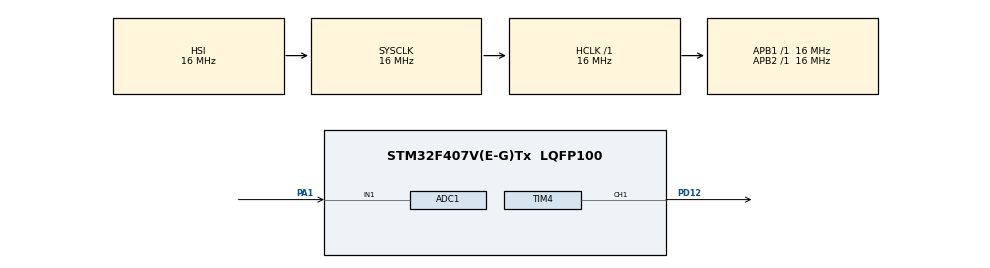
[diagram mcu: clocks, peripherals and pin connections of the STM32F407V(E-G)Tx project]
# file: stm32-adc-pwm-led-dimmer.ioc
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ADC1.Channel-0\#ChannelRegularConversion=ADC_CHANNEL_1
ADC1.NbrOfConversionFlag=1
ADC1.Rank-0\#ChannelRegularConversion=1
ADC1.SamplingTime-0\#ChannelRegularConversion=ADC_SAMPLETIME_3CYCLES
ADC1.master=1
Mcu.Family=STM32F4
Mcu.Name=STM32F407V(E-G)Tx
Mcu.Package=LQFP100
NVIC.PriorityGroup=NVIC_PRIORITYGROUP_4
PA1.Signal=ADCx_IN1
PD12.Signal=S_TIM4_CH1
ProjectManager.HeapSize=0x200
ProjectManager.StackSize=0x400
ProjectManager.TargetToolchain=STM32CubeIDE
RCC.AHBFreq_Value=16000000
RCC.APB1Freq_Value=16000000
RCC.APB2Freq_Value=16000000
RCC.CortexFreq_Value=16000000
RCC.HSE_VALUE=25000000
RCC.HSI_VALUE=16000000
RCC.LSE_VALUE=32768
RCC.SYSCLKFreq_VALUE=16000000
RCC.VCOOutputFreq_Value=192000000
SH.ADCx_IN1.0=ADC1_IN1,IN1
SH.S_TIM4_CH1.0=TIM4_CH1,PWM Generation1 CH1
TIM4.AutoReloadPreload=TIM_AUTORELOAD_PRELOAD_ENABLE
TIM4.Channel-PWM\ Generation1\ CH1=TIM_CHANNEL_1
TIM4.Period=4095
TIM4.Prescaler=15
board=custom

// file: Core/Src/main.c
/* USER CODE BEGIN Header */
/**
 ******************************************************************************
 * @file           : main.c
 * @brief          : Main program body
 ******************************************************************************
 * @attention
 *
 * Copyright (c) 2026 STMicroelectronics.
 * All rights reserved.
 *
 * This software is licensed under terms that can be found in the LICENSE file
 * in the root directory of this software component.
 * If no LICENSE file comes with this software, it is provided AS-IS.
 *
 ******************************************************************************
 */
/* USER CODE END Header */
#include "main.h"

/* USER CODE BEGIN PD */
/**
 * @brief  Sampling period between two ADC conversions (in milliseconds).
 */
#define ADC_SAMPLING_PERIOD_MS  (20U)
/* USER CODE END PD */

ADC_HandleTypeDef hadc1;
TIM_HandleTypeDef htim4;

void SystemClock_Config(void);
static void MX_GPIO_Init(void);
static void MX_ADC1_Init(void);
static void MX_TIM4_Init(void);
/* USER CODE BEGIN PFP */
static uint16_t ReadAdcValue(void);
/* USER CODE END PFP */

/* USER CODE BEGIN 0 */
/**
 * @brief  Read the potentiometer ADC value.
 * @retval 12-bit ADC conversion result (0-4095).
 */
static uint16_t ReadAdcValue(void)
{
	uint16_t adc_value = 0U;

	if (HAL_ADC_Start(&hadc1) != HAL_OK)
	{
		Error_Handler();
	}

	if (HAL_ADC_PollForConversion(&hadc1, 1U) != HAL_OK)
	{
		Error_Handler();
	}

	adc_value = (uint16_t) HAL_ADC_GetValue(&hadc1);

	if (HAL_ADC_Stop(&hadc1) != HAL_OK)
	{
		Error_Handler();
	}

	return adc_value;
}
/* USER CODE END 0 */

int main(void)
{
	/* USER CODE BEGIN 1 */
	uint16_t adc_value = 0U;
	/* USER CODE END 1 */

	/* MCU Configuration--------------------------------------------------------*/

	/* Reset of all peripherals, Initializes the Flash interface and the Systick. */
	HAL_Init();

	/* Configure the system clock */
	SystemClock_Config();

	/* Initialize all configured peripherals */
	MX_GPIO_Init();
	MX_ADC1_Init();
	MX_TIM4_Init();
	/* USER CODE BEGIN 2 */
	if (HAL_TIM_PWM_Start(&htim4, TIM_CHANNEL_1) != HAL_OK)
	{
		Error_Handler();
	}
	/* USER CODE END 2 */

	/* Infinite loop */
	/* USER CODE BEGIN WHILE */
	while (1)
	{
		adc_value = ReadAdcValue();
		__HAL_TIM_SET_COMPARE(&htim4, TIM_CHANNEL_1, adc_value);
		HAL_Delay(ADC_SAMPLING_PERIOD_MS);
		/* USER CODE END WHILE */

	}
}

void SystemClock_Config(void)
{
	RCC_OscInitTypeDef RCC_OscInitStruct = { 0 };
	RCC_ClkInitTypeDef RCC_ClkInitStruct = { 0 };

	/** Configure the main internal regulator output voltage
	 */
	__HAL_RCC_PWR_CLK_ENABLE();
	__HAL_PWR_VOLTAGESCALING_CONFIG(PWR_REGULATOR_VOLTAGE_SCALE1);

	/** Initializes the RCC Oscillators according to the specified parameters
	 * in the RCC_OscInitTypeDef structure.
	 */
	RCC_OscInitStruct.OscillatorType = RCC_OSCILLATORTYPE_HSI;
	RCC_OscInitStruct.HSIState = RCC_HSI_ON;
	RCC_OscInitStruct.HSICalibrationValue = RCC_HSICALIBRATION_DEFAULT;
	RCC_OscInitStruct.PLL.PLLState = RCC_PLL_NONE;
	if (HAL_RCC_OscConfig(&RCC_OscInitStruct) != HAL_OK) {
		Error_Handler();
	}

	/** Initializes the CPU, AHB and APB buses clocks
	 */
	RCC_ClkInitStruct.ClockType = RCC_CLOCKTYPE_HCLK | RCC_CLOCKTYPE_SYSCLK
			| RCC_CLOCKTYPE_PCLK1 | RCC_CLOCKTYPE_PCLK2;
	RCC_ClkInitStruct.SYSCLKSource = RCC_SYSCLKSOURCE_HSI;
	RCC_ClkInitStruct.AHBCLKDivider = RCC_SYSCLK_DIV1;
	RCC_ClkInitStruct.APB1CLKDivider = RCC_HCLK_DIV1;
	RCC_ClkInitStruct.APB2CLKDivider = RCC_HCLK_DIV1;

	if (HAL_RCC_ClockConfig(&RCC_ClkInitStruct, FLASH_LATENCY_0) != HAL_OK) {
		Error_Handler();
	}
}

static void MX_ADC1_Init(void)
{

	ADC_ChannelConfTypeDef sConfig = { 0 };

	/** Configure the global features of the ADC (Clock, Resolution, Data Alignment and number of conversion)
	 */
	hadc1.Instance = ADC1;
	hadc1.Init.ClockPrescaler = ADC_CLOCK_SYNC_PCLK_DIV2;
	hadc1.Init.Resolution = ADC_RESOLUTION_12B;
	hadc1.Init.ScanConvMode = DISABLE;
	hadc1.Init.ContinuousConvMode = DISABLE;
	hadc1.Init.DiscontinuousConvMode = DISABLE;
	hadc1.Init.ExternalTrigConvEdge = ADC_EXTERNALTRIGCONVEDGE_NONE;
	hadc1.Init.ExternalTrigConv = ADC_SOFTWARE_START;
	hadc1.Init.DataAlign = ADC_DATAALIGN_RIGHT;
	hadc1.Init.NbrOfConversion = 1;
	hadc1.Init.DMAContinuousRequests = DISABLE;
	hadc1.Init.EOCSelection = ADC_EOC_SINGLE_CONV;
	if (HAL_ADC_Init(&hadc1) != HAL_OK) {
		Error_Handler();
	}

	/** Configure for the selected ADC regular channel its corresponding rank in the sequencer and its sample time.
	 */
	sConfig.Channel = ADC_CHANNEL_1;
	sConfig.Rank = 1;
	sConfig.SamplingTime = ADC_SAMPLETIME_3CYCLES;
	if (HAL_ADC_ConfigChannel(&hadc1, &sConfig) != HAL_OK) {
		Error_Handler();
	}

}

static void MX_TIM4_Init(void)
{

	TIM_MasterConfigTypeDef sMasterConfig = { 0 };
	TIM_OC_InitTypeDef sConfigOC = { 0 };

	htim4.Instance = TIM4;
	htim4.Init.Prescaler = 15;
	htim4.Init.CounterMode = TIM_COUNTERMODE_UP;
	htim4.Init.Period = 4095;
	htim4.Init.ClockDivision = TIM_CLOCKDIVISION_DIV1;
	htim4.Init.AutoReloadPreload = TIM_AUTORELOAD_PRELOAD_ENABLE;
	if (HAL_TIM_PWM_Init(&htim4) != HAL_OK) {
		Error_Handler();
	}
	sMasterConfig.MasterOutputTrigger = TIM_TRGO_RESET;
	sMasterConfig.MasterSlaveMode = TIM_MASTERSLAVEMODE_DISABLE;
	if (HAL_TIMEx_MasterConfigSynchronization(&htim4, &sMasterConfig)
			!= HAL_OK) {
		Error_Handler();
	}
	sConfigOC.OCMode = TIM_OCMODE_PWM1;
	sConfigOC.Pulse = 0;
	sConfigOC.OCPolarity = TIM_OCPOLARITY_HIGH;
	sConfigOC.OCFastMode = TIM_OCFAST_DISABLE;
	if (HAL_TIM_PWM_ConfigChannel(&htim4, &sConfigOC, TIM_CHANNEL_1)
			!= HAL_OK) {
		Error_Handler();
	}
	HAL_TIM_MspPostInit(&htim4);

}

static void MX_GPIO_Init(void)
{

	/* GPIO Ports Clock Enable */
	__HAL_RCC_GPIOA_CLK_ENABLE();
	__HAL_RCC_GPIOD_CLK_ENABLE();

}

void Error_Handler(void)
{
	__disable_irq();
	while (1) {
	}
}
